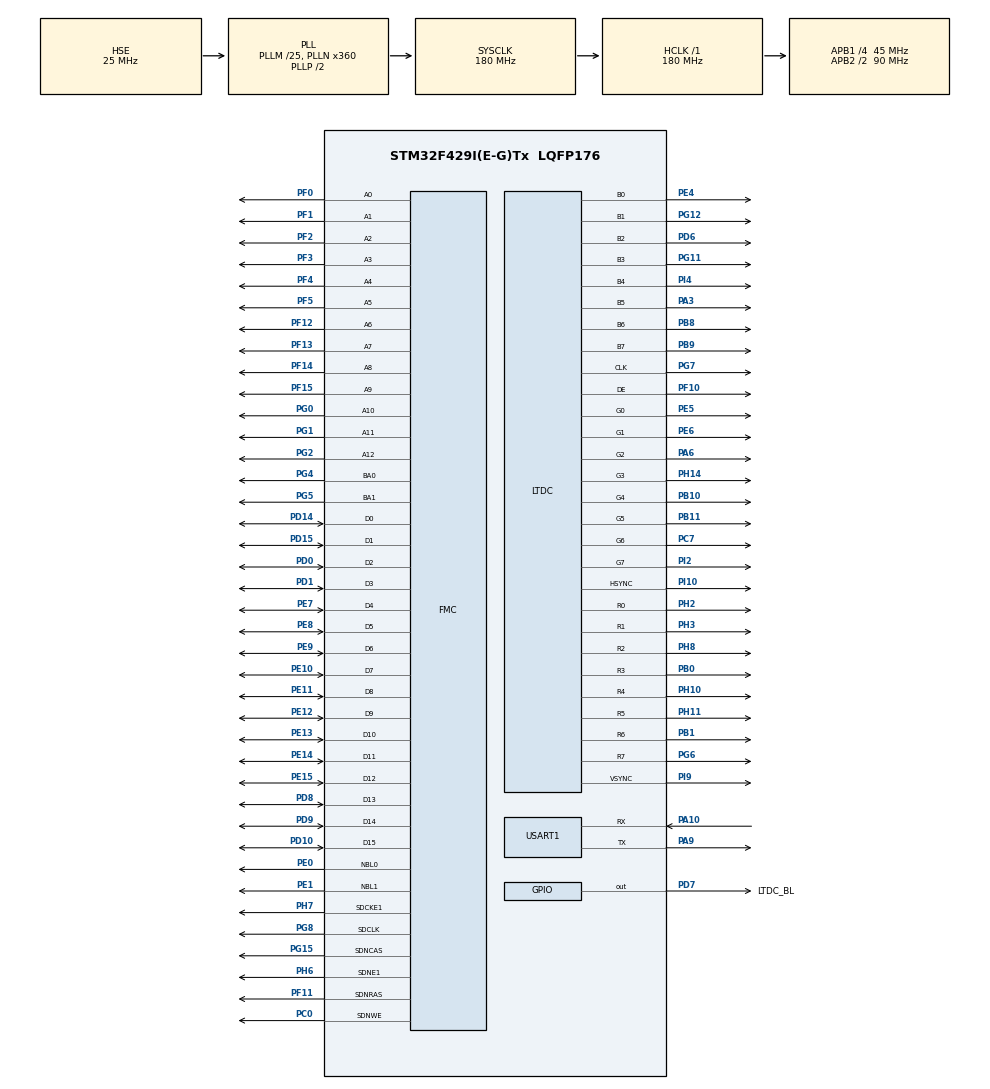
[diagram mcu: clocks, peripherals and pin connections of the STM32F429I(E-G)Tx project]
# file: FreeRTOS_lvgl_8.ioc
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DMA2D.ColorMode=DMA2D_OUTPUT_RGB565
DMA2D.Mode=DMA2D_M2M
FMC.CASLatency1=FMC_SDRAM_CAS_LATENCY_3
FMC.ExitSelfRefreshDelay1=7
FMC.LoadToActiveDelay1=2
FMC.RCDDelay1=2
FMC.RPDelay1=2
FMC.RPDelay2=2
FMC.ReadPipeDelay1=FMC_SDRAM_RPIPE_DELAY_1
FMC.ReadPipeDelay2=FMC_SDRAM_RPIPE_DELAY_1
FMC.RowCycleDelay1=7
FMC.RowCycleDelay2=7
FMC.SDClockPeriod1=FMC_SDRAM_CLOCK_PERIOD_2
FMC.SDClockPeriod2=FMC_SDRAM_CLOCK_PERIOD_2
FMC.SelfRefreshTime1=4
FMC.WriteRecoveryTime1=3
FREERTOS.Tasks01=LVGLTask,24,2048,StartLVGLTask,Default,NULL,Dynamic,NULL,NULL;TimesTask,24,128,StartTimesTask,Default,NULL,Dynamic,NULL,NULL
FREERTOS.configMINIMAL_STACK_SIZE=128
LTDC.ActiveW=800
LTDC.Alpha_L0=255
LTDC.DEPolarity=LTDC_DEPOLARITY_AL
LTDC.FBStartAdress_L0=LAYER0_ADDR
LTDC.HBP=46
LTDC.HFP=22
LTDC.HSPolarity=LTDC_HSPOLARITY_AL
LTDC.HSync=1
LTDC.ImageHeight_L0=LCD_HEIGHT
LTDC.ImageWidth_L0=LCD_WIDTH
LTDC.Layers=0
LTDC.PCPolarity=LTDC_PCPOLARITY_IPC
LTDC.PixelFormat_L0=LTDC_PIXEL_FORMAT_RGB565
LTDC.VBP=23
LTDC.VFP=22
LTDC.VSPolarity=LTDC_VSPOLARITY_AL
LTDC.VSync=1
LTDC.WindowX1_L0=800
LTDC.WindowY1_L0=480
Mcu.Family=STM32F4
Mcu.Name=STM32F429I(E-G)Tx
Mcu.Package=LQFP176
Mcu.UserConstants=LAYER0_ADDR,0xD0000000;LCD_WIDTH,800;LCD_HEIGHT,480
NVIC.DMA2D_IRQn=true\:5\:0\:false\:true\:true\:2\:true\:true\:true
NVIC.PriorityGroup=NVIC_PRIORITYGROUP_4
NVIC.TIM2_IRQn=true\:0\:0\:false\:false\:true\:false\:false\:true
NVIC.TimeBase=TIM2_IRQn
NVIC.TimeBaseIP=TIM2
NVIC.USART1_IRQn=true\:5\:0\:false\:true\:true\:1\:true\:true\:true
PA10.Mode=Asynchronous
PA10.Signal=USART1_RX
PA3.GPIO_Speed=GPIO_SPEED_FREQ_VERY_HIGH
PA3.Mode=RGB888
PA3.Signal=LTDC_B5
PA6.GPIO_Speed=GPIO_SPEED_FREQ_VERY_HIGH
PA6.Mode=RGB888
PA6.Signal=LTDC_G2
PA9.Mode=Asynchronous
PA9.Signal=USART1_TX
PB0.GPIO_Speed=GPIO_SPEED_FREQ_VERY_HIGH
PB0.Mode=RGB888
PB0.Signal=LTDC_R3
PB1.GPIO_Speed=GPIO_SPEED_FREQ_VERY_HIGH
PB1.Mode=RGB888
PB1.Signal=LTDC_R6
PB10.GPIO_Speed=GPIO_SPEED_FREQ_VERY_HIGH
PB10.Mode=RGB888
PB10.Signal=LTDC_G4
PB11.GPIO_Speed=GPIO_SPEED_FREQ_VERY_HIGH
PB11.Mode=RGB888
PB11.Signal=LTDC_G5
PB8.GPIO_Speed=GPIO_SPEED_FREQ_VERY_HIGH
PB8.Mode=RGB888
PB8.Signal=LTDC_B6
PB9.GPIO_Speed=GPIO_SPEED_FREQ_VERY_HIGH
PB9.Mode=RGB888
PB9.Signal=LTDC_B7
PC0.Signal=FMC_SDNWE
PC14/OSC32_IN.Mode=LSE-External-Oscillator
PC14/OSC32_IN.Signal=RCC_OSC32_IN
PC15/OSC32_OUT.Mode=LSE-External-Oscillator
PC15/OSC32_OUT.Signal=RCC_OSC32_OUT
PC7.GPIO_Speed=GPIO_SPEED_FREQ_VERY_HIGH
PC7.Mode=RGB888
PC7.Signal=LTDC_G6
PD0.Signal=FMC_D2_DA2
PD1.Signal=FMC_D3_DA3
PD10.Signal=FMC_D15_DA15
PD14.Signal=FMC_D0_DA0
PD15.Signal=FMC_D1_DA1
PD6.GPIO_Speed=GPIO_SPEED_FREQ_VERY_HIGH
PD6.Mode=RGB888
PD6.Signal=LTDC_B2
PD7.GPIO_Label=LTDC_BL
PD7.GPIO_PuPd=GPIO_PULLUP
PD7.GPIO_Speed=GPIO_SPEED_FREQ_MEDIUM
PD7.Signal=GPIO_Output
PD8.Signal=FMC_D13_DA13
PD9.Signal=FMC_D14_DA14
PE0.Signal=FMC_NBL0
PE1.Signal=FMC_NBL1
PE10.Signal=FMC_D7_DA7
PE11.Signal=FMC_D8_DA8
PE12.Signal=FMC_D9_DA9
PE13.Signal=FMC_D10_DA10
PE14.Signal=FMC_D11_DA11
PE15.Signal=FMC_D12_DA12
PE4.GPIO_Speed=GPIO_SPEED_FREQ_VERY_HIGH
PE4.Mode=RGB888
PE4.Signal=LTDC_B0
PE5.GPIO_Speed=GPIO_SPEED_FREQ_VERY_HIGH
PE5.Mode=RGB888
PE5.Signal=LTDC_G0
PE6.GPIO_Speed=GPIO_SPEED_FREQ_VERY_HIGH
PE6.Mode=RGB888
PE6.Signal=LTDC_G1
PE7.Signal=FMC_D4_DA4
PE8.Signal=FMC_D5_DA5
PE9.Signal=FMC_D6_DA6
PF0.Signal=FMC_A0
PF1.Signal=FMC_A1
PF10.GPIO_Speed=GPIO_SPEED_FREQ_VERY_HIGH
PF10.Mode=RGB888
PF10.Signal=LTDC_DE
PF11.Signal=FMC_SDNRAS
PF12.Signal=FMC_A6
PF13.Signal=FMC_A7
PF14.Signal=FMC_A8
PF15.Signal=FMC_A9
PF2.Signal=FMC_A2
PF3.Signal=FMC_A3
PF4.Signal=FMC_A4
PF5.Signal=FMC_A5
PG0.Signal=FMC_A10
PG1.Signal=FMC_A11
PG11.GPIO_Speed=GPIO_SPEED_FREQ_VERY_HIGH
PG11.Mode=RGB888
PG11.Signal=LTDC_B3
PG12.GPIO_Speed=GPIO_SPEED_FREQ_VERY_HIGH
PG12.Mode=RGB888
PG12.Signal=LTDC_B1
PG15.Signal=FMC_SDNCAS
PG2.Signal=FMC_A12
PG4.Signal=FMC_A14_BA0
PG5.Signal=FMC_A15_BA1
PG6.GPIO_Speed=GPIO_SPEED_FREQ_VERY_HIGH
PG6.Mode=RGB888
PG6.Signal=LTDC_R7
PG7.GPIO_Speed=GPIO_SPEED_FREQ_VERY_HIGH
PG7.Mode=RGB888
PG7.Signal=LTDC_CLK
PG8.Signal=FMC_SDCLK
PH0/OSC_IN.Mode=HSE-External-Oscillator
PH0/OSC_IN.Signal=RCC_OSC_IN
PH1/OSC_OUT.Mode=HSE-External-Oscillator
PH1/OSC_OUT.Signal=RCC_OSC_OUT
PH10.GPIO_Speed=GPIO_SPEED_FREQ_VERY_HIGH
PH10.Mode=RGB888
PH10.Signal=LTDC_R4
PH11.GPIO_Speed=GPIO_SPEED_FREQ_VERY_HIGH
PH11.Mode=RGB888
PH11.Signal=LTDC_R5
PH14.GPIO_Speed=GPIO_SPEED_FREQ_VERY_HIGH
PH14.Mode=RGB888
PH14.Signal=LTDC_G3
PH2.GPIO_Speed=GPIO_SPEED_FREQ_VERY_HIGH
PH2.Mode=RGB888
PH2.Signal=LTDC_R0
PH3.GPIO_Speed=GPIO_SPEED_FREQ_VERY_HIGH
PH3.Mode=RGB888
PH3.Signal=LTDC_R1
PH6.Mode=SdramChipSelect2_1
PH6.Signal=FMC_SDNE1
PH7.Mode=SdramChipSelect2_1
PH7.Signal=FMC_SDCKE1
PH8.GPIO_Speed=GPIO_SPEED_FREQ_VERY_HIGH
PH8.Mode=RGB888
PH8.Signal=LTDC_R2
PI10.GPIO_Speed=GPIO_SPEED_FREQ_VERY_HIGH
PI10.Mode=RGB888
PI10.Signal=LTDC_HSYNC
PI2.GPIO_Speed=GPIO_SPEED_FREQ_VERY_HIGH
PI2.Mode=RGB888
PI2.Signal=LTDC_G7
PI4.GPIO_Speed=GPIO_SPEED_FREQ_VERY_HIGH
PI4.Mode=RGB888
PI4.Signal=LTDC_B4
PI9.GPIO_Speed=GPIO_SPEED_FREQ_VERY_HIGH
PI9.Mode=RGB888
PI9.Signal=LTDC_VSYNC
ProjectManager.HeapSize=0x2000
ProjectManager.StackSize=0x4000
ProjectManager.TargetToolchain=MDK-ARM V5.32
RCC.48MHZClocksFreq_Value=90000000
RCC.AHBFreq_Value=180000000
RCC.APB1CLKDivider=RCC_HCLK_DIV4
RCC.APB1Freq_Value=45000000
RCC.APB1TimFreq_Value=90000000
RCC.APB2CLKDivider=RCC_HCLK_DIV2
RCC.APB2Freq_Value=90000000
RCC.APB2TimFreq_Value=180000000
RCC.CortexFreq_Value=180000000
RCC.EnbaleCSS=true
RCC.HCLKFreq_Value=180000000
RCC.HSE_VALUE=25000000
RCC.HSI_VALUE=16000000
RCC.PLLM=25
RCC.PLLN=360
RCC.PLLSAIDivR=RCC_PLLSAIDIVR_4
RCC.PLLSAIN=180
RCC.PLLSourceVirtual=RCC_PLLSOURCE_HSE
RCC.PWREXT_OverDrive=PWREXT_OverDrive_ACTIVATED
RCC.PWR_Regulator_Voltage_Scale=PWR_REGULATOR_VOLTAGE_SCALE1
RCC.SYSCLKFreq_VALUE=180000000
RCC.SYSCLKSource=RCC_SYSCLKSOURCE_PLLCLK
RCC.VCOOutputFreq_Value=360000000
SH.FMC_A0.0=FMC_A0,13b-sda1
SH.FMC_A1.0=FMC_A1,13b-sda1
SH.FMC_A10.0=FMC_A10,13b-sda1
SH.FMC_A11.0=FMC_A11,13b-sda1
SH.FMC_A12.0=FMC_A12,13b-sda1
SH.FMC_A14_BA0.0=FMC_BA0,FourSdramBanks1
SH.FMC_A15_BA1.0=FMC_BA1,FourSdramBanks1
SH.FMC_A2.0=FMC_A2,13b-sda1
SH.FMC_A3.0=FMC_A3,13b-sda1
SH.FMC_A4.0=FMC_A4,13b-sda1
SH.FMC_A5.0=FMC_A5,13b-sda1
SH.FMC_A6.0=FMC_A6,13b-sda1
SH.FMC_A7.0=FMC_A7,13b-sda1
SH.FMC_A8.0=FMC_A8,13b-sda1
SH.FMC_A9.0=FMC_A9,13b-sda1
SH.FMC_D0_DA0.0=FMC_D0,sd-16b-d1
SH.FMC_D10_DA10.0=FMC_D10,sd-16b-d1
SH.FMC_D11_DA11.0=FMC_D11,sd-16b-d1
SH.FMC_D12_DA12.0=FMC_D12,sd-16b-d1
SH.FMC_D13_DA13.0=FMC_D13,sd-16b-d1
SH.FMC_D14_DA14.0=FMC_D14,sd-16b-d1
SH.FMC_D15_DA15.0=FMC_D15,sd-16b-d1
SH.FMC_D1_DA1.0=FMC_D1,sd-16b-d1
SH.FMC_D2_DA2.0=FMC_D2,sd-16b-d1
SH.FMC_D3_DA3.0=FMC_D3,sd-16b-d1
SH.FMC_D4_DA4.0=FMC_D4,sd-16b-d1
SH.FMC_D5_DA5.0=FMC_D5,sd-16b-d1
SH.FMC_D6_DA6.0=FMC_D6,sd-16b-d1
SH.FMC_D7_DA7.0=FMC_D7,sd-16b-d1
SH.FMC_D8_DA8.0=FMC_D8,sd-16b-d1
SH.FMC_D9_DA9.0=FMC_D9,sd-16b-d1
SH.FMC_NBL0.0=FMC_NBL0,Sd2ByteEnable1
SH.FMC_NBL1.0=FMC_NBL1,Sd2ByteEnable1
SH.FMC_SDCLK.0=FMC_SDCLK,13b-sda1
SH.FMC_SDNCAS.0=FMC_SDNCAS,13b-sda1
SH.FMC_SDNRAS.0=FMC_SDNRAS,13b-sda1
SH.FMC_SDNWE.0=FMC_SDNWE,13b-sda1
USART1.VirtualMode=VM_ASYNC
VP_DMA2D_VS_DMA2D.Mode=DMA2D_Activate
VP_FREERTOS_VS_CMSIS_V2.Mode=CMSIS_V2
VP_SYS_VS_tim2.Mode=TIM2
board=custom

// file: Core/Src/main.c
/* USER CODE BEGIN Header */
/**
  ******************************************************************************
  * @file           : main.c
  * @brief          : Main program body
  ******************************************************************************
  * @attention
  *
  * <h2><center>&copy; Copyright (c) 2021 STMicroelectronics.
  * All rights reserved.</center></h2>
  *
  * This software component is licensed by ST under Ultimate Liberty license
  * SLA0044, the "License"; You may not use this file except in compliance with
  * the License. You may obtain a copy of the License at:
  *                             www.st.com/SLA0044
  *
  ******************************************************************************
  */
/* USER CODE END Header */
#include "main.h"
#include "cmsis_os.h"

/* USER CODE BEGIN Includes */
#include "lvgl.h"
#include "lv_port_disp.h"
#include "lv_port_indev.h"
#include "lv_demo_widgets.h"

#include "bsp_lcd.h"
#include "bsp_sdram.h"
/* USER CODE END Includes */

/* USER CODE BEGIN PTD */

extern uint16_t _aclogo_IKKEM_200[];
// lvgl中断刷新
extern __IO bool g_gpu_state;
extern lv_disp_drv_t *g_disp_drv;
/* USER CODE END PTD */

DMA2D_HandleTypeDef hdma2d;

LTDC_HandleTypeDef hltdc;

UART_HandleTypeDef huart1;

SDRAM_HandleTypeDef hsdram1;

/* Definitions for LVGLTask */
osThreadId_t LVGLTaskHandle;
const osThreadAttr_t LVGLTask_attributes = {
  .name = "LVGLTask",
  .stack_size = 2048 * 4,
  .priority = (osPriority_t) osPriorityNormal,
};
/* Definitions for TimesTask */
osThreadId_t TimesTaskHandle;
const osThreadAttr_t TimesTask_attributes = {
  .name = "TimesTask",
  .stack_size = 128 * 4,
  .priority = (osPriority_t) osPriorityNormal,
};

void SystemClock_Config(void);
static void MX_GPIO_Init(void);
static void MX_DMA2D_Init(void);
static void MX_FMC_Init(void);
static void MX_LTDC_Init(void);
static void MX_USART1_UART_Init(void);
void StartLVGLTask(void *argument);
void StartTimesTask(void *argument);

static void MX_NVIC_Init(void);
/* USER CODE BEGIN PFP */
void mDMA2Dcallvack(DMA2D_HandleTypeDef *hdma2d);
/* USER CODE END PFP */

int main(void)
{

  /* MCU Configuration--------------------------------------------------------*/

  /* Reset of all peripherals, Initializes the Flash interface and the Systick. */
  HAL_Init();

  /* Configure the system clock */
  SystemClock_Config();

  /* Initialize all configured peripherals */
  MX_GPIO_Init();
  MX_DMA2D_Init();
  MX_FMC_Init();
  MX_LTDC_Init();
  MX_USART1_UART_Init();

  /* Initialize interrupts */
  MX_NVIC_Init();
  /* USER CODE BEGIN 2 */
  // 必须初始化io，否则产生拖影
  LCD_GPIO_Config();
  HAL_GPIO_WritePin(LTDC_BL_GPIO_Port, LTDC_BL_Pin, GPIO_PIN_SET);  /* 开背光*/
  LCD_Clear(LCD_COLOR_WHITE);
  /* USER CODE END 2 */

  /* Init scheduler */
  osKernelInitialize();

  /* Create the thread(s) */
  /* creation of LVGLTask */
  LVGLTaskHandle = osThreadNew(StartLVGLTask, NULL, &LVGLTask_attributes);

  /* creation of TimesTask */
  TimesTaskHandle = osThreadNew(StartTimesTask, NULL, &TimesTask_attributes);

  /* Start scheduler */
  osKernelStart();

  /* We should never get here as control is now taken by the scheduler */
  /* Infinite loop */
  while (1)
  {

  }
}

void SystemClock_Config(void)
{
  RCC_OscInitTypeDef RCC_OscInitStruct = {0};
  RCC_ClkInitTypeDef RCC_ClkInitStruct = {0};

  /** Configure the main internal regulator output voltage
  */
  __HAL_RCC_PWR_CLK_ENABLE();
  __HAL_PWR_VOLTAGESCALING_CONFIG(PWR_REGULATOR_VOLTAGE_SCALE1);
  /** Initializes the RCC Oscillators according to the specified parameters
  * in the RCC_OscInitTypeDef structure.
  */
  RCC_OscInitStruct.OscillatorType = RCC_OSCILLATORTYPE_HSE;
  RCC_OscInitStruct.HSEState = RCC_HSE_ON;
  RCC_OscInitStruct.PLL.PLLState = RCC_PLL_ON;
  RCC_OscInitStruct.PLL.PLLSource = RCC_PLLSOURCE_HSE;
  RCC_OscInitStruct.PLL.PLLM = 25;
  RCC_OscInitStruct.PLL.PLLN = 360;
  RCC_OscInitStruct.PLL.PLLP = RCC_PLLP_DIV2;
  RCC_OscInitStruct.PLL.PLLQ = 4;
  if (HAL_RCC_OscConfig(&RCC_OscInitStruct) != HAL_OK)
  {
    Error_Handler();
  }
  /** Activate the Over-Drive mode
  */
  if (HAL_PWREx_EnableOverDrive() != HAL_OK)
  {
    Error_Handler();
  }
  /** Initializes the CPU, AHB and APB buses clocks
  */
  RCC_ClkInitStruct.ClockType = RCC_CLOCKTYPE_HCLK|RCC_CLOCKTYPE_SYSCLK
                              |RCC_CLOCKTYPE_PCLK1|RCC_CLOCKTYPE_PCLK2;
  RCC_ClkInitStruct.SYSCLKSource = RCC_SYSCLKSOURCE_PLLCLK;
  RCC_ClkInitStruct.AHBCLKDivider = RCC_SYSCLK_DIV1;
  RCC_ClkInitStruct.APB1CLKDivider = RCC_HCLK_DIV4;
  RCC_ClkInitStruct.APB2CLKDivider = RCC_HCLK_DIV2;

  if (HAL_RCC_ClockConfig(&RCC_ClkInitStruct, FLASH_LATENCY_5) != HAL_OK)
  {
    Error_Handler();
  }
  /** Enables the Clock Security System
  */
  HAL_RCC_EnableCSS();
}

/**
  * @brief NVIC Configuration.
  * @retval None
  */
static void MX_NVIC_Init(void)
{
  /* USART1_IRQn interrupt configuration */
  HAL_NVIC_SetPriority(USART1_IRQn, 5, 0);
  HAL_NVIC_EnableIRQ(USART1_IRQn);
  /* DMA2D_IRQn interrupt configuration */
  HAL_NVIC_SetPriority(DMA2D_IRQn, 5, 0);
  HAL_NVIC_EnableIRQ(DMA2D_IRQn);
}

static void MX_DMA2D_Init(void)
{

  /* USER CODE BEGIN DMA2D_Init 1 */
  // dma2d完成回调
  hdma2d.XferCpltCallback = mDMA2Dcallvack;
  /* USER CODE END DMA2D_Init 1 */
  hdma2d.Instance = DMA2D;
  hdma2d.Init.Mode = DMA2D_M2M;
  hdma2d.Init.ColorMode = DMA2D_OUTPUT_RGB565;
  hdma2d.Init.OutputOffset = 0;
  hdma2d.LayerCfg[1].InputOffset = 0;
  hdma2d.LayerCfg[1].InputColorMode = DMA2D_INPUT_RGB565;
  hdma2d.LayerCfg[1].AlphaMode = DMA2D_NO_MODIF_ALPHA;
  hdma2d.LayerCfg[1].InputAlpha = 0;
  if (HAL_DMA2D_Init(&hdma2d) != HAL_OK)
  {
    Error_Handler();
  }
  if (HAL_DMA2D_ConfigLayer(&hdma2d, 1) != HAL_OK)
  {
    Error_Handler();
  }
  /* USER CODE BEGIN DMA2D_Init 2 */
//    DMA2D->FGPFCCR = LTDC_PIXEL_FORMAT_RGB565;
  /* USER CODE END DMA2D_Init 2 */

}

static void MX_LTDC_Init(void)
{

  LTDC_LayerCfgTypeDef pLayerCfg = {0};

  hltdc.Instance = LTDC;
  hltdc.Init.HSPolarity = LTDC_HSPOLARITY_AL;
  hltdc.Init.VSPolarity = LTDC_VSPOLARITY_AL;
  hltdc.Init.DEPolarity = LTDC_DEPOLARITY_AL;
  hltdc.Init.PCPolarity = LTDC_PCPOLARITY_IPC;
  hltdc.Init.HorizontalSync = 0;
  hltdc.Init.VerticalSync = 0;
  hltdc.Init.AccumulatedHBP = 46;
  hltdc.Init.AccumulatedVBP = 23;
  hltdc.Init.AccumulatedActiveW = 846;
  hltdc.Init.AccumulatedActiveH = 503;
  hltdc.Init.TotalWidth = 868;
  hltdc.Init.TotalHeigh = 525;
  hltdc.Init.Backcolor.Blue = 0;
  hltdc.Init.Backcolor.Green = 0;
  hltdc.Init.Backcolor.Red = 0;
  if (HAL_LTDC_Init(&hltdc) != HAL_OK)
  {
    Error_Handler();
  }
  pLayerCfg.WindowX0 = 0;
  pLayerCfg.WindowX1 = 800;
  pLayerCfg.WindowY0 = 0;
  pLayerCfg.WindowY1 = 480;
  pLayerCfg.PixelFormat = LTDC_PIXEL_FORMAT_RGB565;
  pLayerCfg.Alpha = 255;
  pLayerCfg.Alpha0 = 0;
  pLayerCfg.BlendingFactor1 = LTDC_BLENDING_FACTOR1_CA;
  pLayerCfg.BlendingFactor2 = LTDC_BLENDING_FACTOR2_CA;
  pLayerCfg.FBStartAdress = LAYER0_ADDR;
  pLayerCfg.ImageWidth = LCD_WIDTH;
  pLayerCfg.ImageHeight = LCD_HEIGHT;
  pLayerCfg.Backcolor.Blue = 0;
  pLayerCfg.Backcolor.Green = 0;
  pLayerCfg.Backcolor.Red = 0;
  if (HAL_LTDC_ConfigLayer(&hltdc, &pLayerCfg, 0) != HAL_OK)
  {
    Error_Handler();
  }

}

static void MX_USART1_UART_Init(void)
{

  huart1.Instance = USART1;
  huart1.Init.BaudRate = 115200;
  huart1.Init.WordLength = UART_WORDLENGTH_8B;
  huart1.Init.StopBits = UART_STOPBITS_1;
  huart1.Init.Parity = UART_PARITY_NONE;
  huart1.Init.Mode = UART_MODE_TX_RX;
  huart1.Init.HwFlowCtl = UART_HWCONTROL_NONE;
  huart1.Init.OverSampling = UART_OVERSAMPLING_16;
  if (HAL_UART_Init(&huart1) != HAL_OK)
  {
    Error_Handler();
  }

}

/* FMC initialization function */
static void MX_FMC_Init(void)
{

  FMC_SDRAM_TimingTypeDef SdramTiming = {0};

  /** Perform the SDRAM1 memory initialization sequence
  */
  hsdram1.Instance = FMC_SDRAM_DEVICE;
  /* hsdram1.Init */
  hsdram1.Init.SDBank = FMC_SDRAM_BANK2;
  hsdram1.Init.ColumnBitsNumber = FMC_SDRAM_COLUMN_BITS_NUM_8;
  hsdram1.Init.RowBitsNumber = FMC_SDRAM_ROW_BITS_NUM_13;
  hsdram1.Init.MemoryDataWidth = FMC_SDRAM_MEM_BUS_WIDTH_16;
  hsdram1.Init.InternalBankNumber = FMC_SDRAM_INTERN_BANKS_NUM_4;
  hsdram1.Init.CASLatency = FMC_SDRAM_CAS_LATENCY_3;
  hsdram1.Init.WriteProtection = FMC_SDRAM_WRITE_PROTECTION_DISABLE;
  hsdram1.Init.SDClockPeriod = FMC_SDRAM_CLOCK_PERIOD_2;
  hsdram1.Init.ReadBurst = FMC_SDRAM_RBURST_DISABLE;
  hsdram1.Init.ReadPipeDelay = FMC_SDRAM_RPIPE_DELAY_1;
  /* SdramTiming */
  SdramTiming.LoadToActiveDelay = 2;
  SdramTiming.ExitSelfRefreshDelay = 7;
  SdramTiming.SelfRefreshTime = 4;
  SdramTiming.RowCycleDelay = 7;
  SdramTiming.WriteRecoveryTime = 3;
  SdramTiming.RPDelay = 2;
  SdramTiming.RCDDelay = 2;

  if (HAL_SDRAM_Init(&hsdram1, &SdramTiming) != HAL_OK)
  {
    Error_Handler( );
  }

  /* USER CODE BEGIN FMC_Init 2 */
  SDRAM_InitSequence();
  /* USER CODE END FMC_Init 2 */
}

static void MX_GPIO_Init(void)
{
  GPIO_InitTypeDef GPIO_InitStruct = {0};

  /* GPIO Ports Clock Enable */
  __HAL_RCC_GPIOE_CLK_ENABLE();
  __HAL_RCC_GPIOC_CLK_ENABLE();
  __HAL_RCC_GPIOI_CLK_ENABLE();
  __HAL_RCC_GPIOF_CLK_ENABLE();
  __HAL_RCC_GPIOH_CLK_ENABLE();
  __HAL_RCC_GPIOA_CLK_ENABLE();
  __HAL_RCC_GPIOB_CLK_ENABLE();
  __HAL_RCC_GPIOG_CLK_ENABLE();
  __HAL_RCC_GPIOD_CLK_ENABLE();

  /*Configure GPIO pin Output Level */
  HAL_GPIO_WritePin(LTDC_BL_GPIO_Port, LTDC_BL_Pin, GPIO_PIN_RESET);

  /*Configure GPIO pin : LTDC_BL_Pin */
  GPIO_InitStruct.Pin = LTDC_BL_Pin;
  GPIO_InitStruct.Mode = GPIO_MODE_OUTPUT_PP;
  GPIO_InitStruct.Pull = GPIO_PULLUP;
  GPIO_InitStruct.Speed = GPIO_SPEED_FREQ_MEDIUM;
  HAL_GPIO_Init(LTDC_BL_GPIO_Port, &GPIO_InitStruct);

}

/* USER CODE BEGIN 4 */

/**
 * @brief 重定向c库函数printf到串口DEBUG_USART，重定向后可使用printf函数
 * @param {int} ch
 * @param {FILE} *f
 * @return {*}
 */
int fputc(int ch, FILE *f)
{
  HAL_UART_Transmit(&huart1, (uint8_t *)&ch, 1, 0xffff);
  return ch;
}

/**
 * @brief DMA2D传输完成回调，通知lvgl刷新完成
 * @param {DMA2D_HandleTypeDef} *hdma2d
 * @return {*}
 */
void mDMA2Dcallvack(DMA2D_HandleTypeDef *hdma2d){
    if(g_gpu_state){
        g_gpu_state = false;
        lv_disp_flush_ready(g_disp_drv);
    }
}
/* USER CODE END 4 */

void StartLVGLTask(void *argument)
{
  /* USER CODE BEGIN 5 */
    lv_init();
    lv_port_disp_init();
    lv_port_indev_init();
    lv_demo_widgets();
  /* Infinite loop */
  for(;;)
  {

    lv_task_handler();
    osDelay(30);
  }
  /* USER CODE END 5 */
}

void StartTimesTask(void *argument)
{
  /* USER CODE BEGIN StartTimesTask */
  /* Infinite loop */
  for(;;)
  {
    osDelay(100);
  }
  /* USER CODE END StartTimesTask */
}

void HAL_TIM_PeriodElapsedCallback(TIM_HandleTypeDef *htim)
{
  if (htim->Instance == TIM2) {
    HAL_IncTick();
  }
  /* USER CODE BEGIN Callback 1 */
  // lvgl心跳
  if (htim->Instance == TIM2) {
    lv_tick_inc(1);
  }
  /* USER CODE END Callback 1 */
}

void Error_Handler(void)
{
  __disable_irq();
  while (1)
  {
  }
}

/************************ (C) COPYRIGHT STMicroelectronics *****END OF FILE****/
